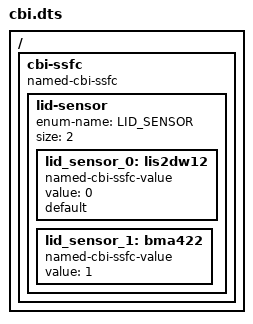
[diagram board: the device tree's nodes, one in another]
/* Copyright 2022 The Chromium OS Authors.
 * Use of this source code is governed by a BSD-style license that can be
 * found in the LICENSE file.
 */

/ {
	/* Craask-specific ssfc fields. */
	cbi-ssfc {
		compatible = "named-cbi-ssfc";
		/*
		 * SSFC field to identify LID motion sensor.
		 */
		lid-sensor {
			enum-name = "LID_SENSOR";
			size = <2>;

			lid_sensor_0: lis2dw12 {
				compatible = "named-cbi-ssfc-value";
				status = "okay";
				value = <0>;
				default;
			};
			lid_sensor_1: bma422 {
				compatible = "named-cbi-ssfc-value";
				status = "okay";
				value = <1>;
			};
		};
	};
};
